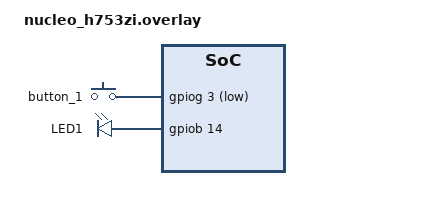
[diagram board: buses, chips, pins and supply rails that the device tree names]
/ {
	aliases {
		my-button = &button_1;
		my-led = &led_1;
	};

	buttons {
		compatible = "gpio-keys";
		debounce-interval-ms = <10>;
		polling-mode;

		button_1: d50 {
			gpios = <&gpiog 3 (GPIO_ACTIVE_LOW | GPIO_PULL_UP)>;
		};
	};
	leds {
		compatible = "gpio-leds";

		led_1: d13 {
			label = "LED1";
			gpios = <&gpiob 14 GPIO_ACTIVE_HIGH>;
		};
	};
};
